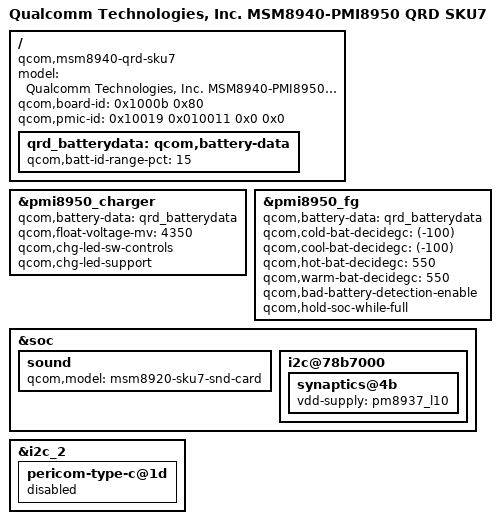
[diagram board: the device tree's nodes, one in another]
/*
 * Copyright (c) 2016, The Linux Foundation. All rights reserved.
 *
 * This program is free software; you can redistribute it and/or modify
 * it under the terms of the GNU General Public License version 2 and
 * only version 2 as published by the Free Software Foundation.
 *
 * This program is distributed in the hope that it will be useful,
 * but WITHOUT ANY WARRANTY; without even the implied warranty of
 * MERCHANTABILITY or FITNESS FOR A PARTICULAR PURPOSE.  See the
 * GNU General Public License for more details.
 */

/dts-v1/;

#include "msm8940.dtsi"
#include "msm8937-pmi8950-qrd-sku1.dtsi"
#include "msm8940-camera-sensor-qrd.dtsi"
#include "msm8940-pinctrl.dtsi"

/ {
	model = "Qualcomm Technologies, Inc. MSM8940-PMI8950 QRD SKU7";
	compatible = "qcom,msm8940-qrd-sku7", "qcom,msm8940-qrd",
		   "qcom,msm8940", "qcom,qrd";
	qcom,board-id= <0x1000b 0x80>;
	qcom,pmic-id = <0x10019 0x010011 0x0 0x0>;
};

/ {
	qrd_batterydata: qcom,battery-data {
		qcom,batt-id-range-pct = <15>;
		#include "batterydata-qrd-sku2-4v35-2590mah.dtsi"
	};
};

&pmi8950_charger {
	qcom,battery-data = <&qrd_batterydata>;
	qcom,float-voltage-mv = <4350>;
	qcom,chg-led-sw-controls;
	qcom,chg-led-support;
	status = "okay";
};

&pmi8950_fg {
	qcom,battery-data = <&qrd_batterydata>;
	qcom,cold-bat-decidegc = <(-100)>;
	qcom,cool-bat-decidegc = <(-100)>;
	qcom,hot-bat-decidegc = <550>;
	qcom,warm-bat-decidegc = <550>;
	qcom,bad-battery-detection-enable;
	qcom,hold-soc-while-full;
};

&soc {
	sound {
		qcom,model = "msm8920-sku7-snd-card";
	};

	i2c@78b7000 {
		synaptics@4b {
			vdd-supply = <&pm8937_l10>;
		};
	};
};

&i2c_2 {
	pericom-type-c@1d {
		status="disabled";
	};
};
